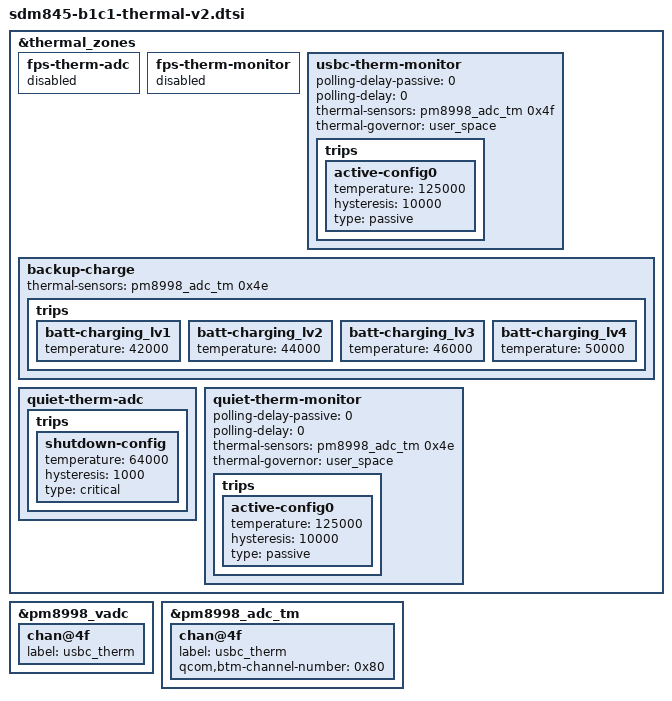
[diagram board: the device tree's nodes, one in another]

/* Supported hardware: B1 EVT1 => B1 EVT2, C1 P1 => C1 EVT1 */

&thermal_zones {
	fps-therm-adc {
		status = "disabled";
	};

	fps-therm-monitor {
		status = "disabled";
	};

	usbc-therm-monitor {
		polling-delay-passive = <0>;
		polling-delay = <0>;
		thermal-sensors = <&pm8998_adc_tm 0x4f>;
		thermal-governor = "user_space";

		trips {
			active-config0 {
				temperature = <125000>;
				hysteresis = <10000>;
				type = "passive";
			};
		};
	};

	backup-charge {
		thermal-sensors = <&pm8998_adc_tm 0x4e>;

		trips {
			batt-charging_lv1 {
				temperature = <42000>;
			};
			batt-charging_lv2 {
				temperature = <44000>;
			};
			batt-charging_lv3 {
				temperature = <46000>;
			};
			batt-charging_lv4 {
				temperature = <50000>;
			};
		};
	};

	quiet-therm-adc {
		trips {
			shutdown-config {
				temperature = <64000>;
				hysteresis = <1000>;
				type = "critical";
			};
		};
	};

	quiet-therm-monitor {
		polling-delay-passive = <0>;
		polling-delay = <0>;
		thermal-sensors = <&pm8998_adc_tm 0x4e>;
		thermal-governor = "user_space";

		trips {
			active-config0 {
				temperature = <125000>;
				hysteresis = <10000>;
				type = "passive";
			};
		};
	};

};

&pm8998_vadc {
	chan@4f {
		label = "usbc_therm";
	};
};

&pm8998_adc_tm {
	chan@4f {
		label = "usbc_therm";
		qcom,btm-channel-number = <0x80>;
	};
};
